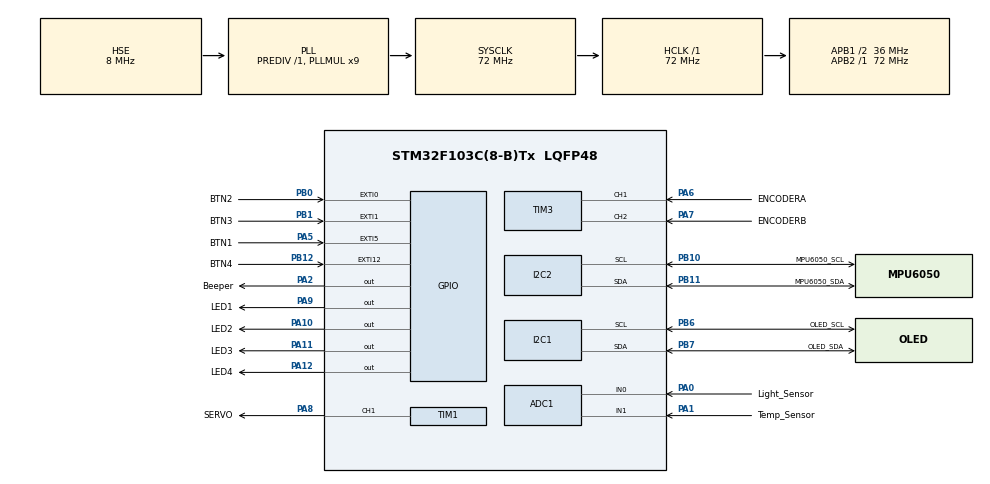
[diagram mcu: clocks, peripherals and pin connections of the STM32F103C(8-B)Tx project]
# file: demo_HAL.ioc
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ADC1.Channel-2\#ChannelRegularConversion=ADC_CHANNEL_0
ADC1.Channel-3\#ChannelRegularConversion=ADC_CHANNEL_1
ADC1.ContinuousConvMode=ENABLE
ADC1.NbrOfConversion=2
ADC1.NbrOfConversionFlag=1
ADC1.Rank-2\#ChannelRegularConversion=1
ADC1.Rank-3\#ChannelRegularConversion=2
ADC1.SamplingTime-2\#ChannelRegularConversion=ADC_SAMPLETIME_239CYCLES_5
ADC1.SamplingTime-3\#ChannelRegularConversion=ADC_SAMPLETIME_239CYCLES_5
ADC1.master=1
Dma.ADC1.0.Direction=DMA_PERIPH_TO_MEMORY
Dma.ADC1.0.Instance=DMA1_Channel1
Dma.ADC1.0.MemDataAlignment=DMA_MDATAALIGN_WORD
Dma.ADC1.0.MemInc=DMA_MINC_ENABLE
Dma.ADC1.0.Mode=DMA_CIRCULAR
Dma.ADC1.0.PeriphDataAlignment=DMA_PDATAALIGN_WORD
Dma.ADC1.0.PeriphInc=DMA_PINC_DISABLE
Dma.ADC1.0.Priority=DMA_PRIORITY_HIGH
Dma.Request0=ADC1
I2C1.I2C_Mode=I2C_Standard
Mcu.Family=STM32F1
Mcu.Name=STM32F103C(8-B)Tx
Mcu.Package=LQFP48
NVIC.DMA1_Channel1_IRQn=true\:0\:0\:false\:false\:true\:false\:true\:true
NVIC.EXTI0_IRQn=true\:2\:0\:true\:false\:true\:true\:true\:true
NVIC.EXTI15_10_IRQn=true\:2\:0\:true\:false\:true\:true\:true\:true
NVIC.EXTI1_IRQn=true\:2\:0\:true\:false\:true\:true\:true\:true
NVIC.EXTI9_5_IRQn=true\:2\:0\:true\:false\:true\:true\:true\:true
NVIC.PriorityGroup=NVIC_PRIORITYGROUP_4
PA0-WKUP.GPIO_Label=Light_Sensor
PA0-WKUP.Signal=SharedAnalog_PA0
PA1.GPIO_Label=Temp_Sensor
PA1.Signal=SharedAnalog_PA1
PA10.GPIO_Label=LED2
PA10.GPIO_Speed=GPIO_SPEED_FREQ_HIGH
PA10.PinState=GPIO_PIN_SET
PA10.Signal=GPIO_Output
PA11.GPIO_Label=LED3
PA11.GPIO_Speed=GPIO_SPEED_FREQ_HIGH
PA11.PinState=GPIO_PIN_SET
PA11.Signal=GPIO_Output
PA12.GPIO_Label=LED4
PA12.GPIO_Speed=GPIO_SPEED_FREQ_HIGH
PA12.PinState=GPIO_PIN_SET
PA12.Signal=GPIO_Output
PA13.Mode=Serial_Wire
PA13.Signal=SYS_JTMS-SWDIO
PA14.Mode=Serial_Wire
PA14.Signal=SYS_JTCK-SWCLK
PA2.GPIO_Label=Beeper
PA2.GPIO_Speed=GPIO_SPEED_FREQ_MEDIUM
PA2.PinState=GPIO_PIN_SET
PA2.Signal=GPIO_Output
PA5.GPIO_Label=BTN1
PA5.GPIO_ModeDefaultEXTI=GPIO_MODE_IT_FALLING
PA5.GPIO_PuPd=GPIO_PULLUP
PA5.Signal=GPXTI5
PA6.GPIO_Label=ENCODERA
PA6.GPIO_ModeDefaultPP=GPIO_MODE_AF_PP
PA6.GPIO_PuPd=GPIO_PULLUP
PA6.GPIO_Speed=GPIO_SPEED_FREQ_HIGH
PA6.Signal=S_TIM3_CH1
PA7.GPIO_Label=ENCODERB
PA7.GPIO_PuPd=GPIO_PULLUP
PA7.GPIO_Speed=GPIO_SPEED_FREQ_HIGH
PA7.Signal=S_TIM3_CH2
PA8.GPIO_Label=SERVO
PA8.GPIO_PuPd=GPIO_PULLUP
PA8.Signal=S_TIM1_CH1
PA9.GPIO_Label=LED1
PA9.GPIO_Speed=GPIO_SPEED_FREQ_HIGH
PA9.PinState=GPIO_PIN_SET
PA9.Signal=GPIO_Output
PB0.GPIO_Label=BTN2
PB0.GPIO_ModeDefaultEXTI=GPIO_MODE_IT_FALLING
PB0.GPIO_PuPd=GPIO_PULLUP
PB0.Signal=GPXTI0
PB1.GPIO_Label=BTN3
PB1.GPIO_ModeDefaultEXTI=GPIO_MODE_IT_FALLING
PB1.GPIO_PuPd=GPIO_PULLUP
PB1.Signal=GPXTI1
PB10.GPIO_Label=MPU6050_SCL
PB10.Mode=I2C
PB10.Signal=I2C2_SCL
PB11.GPIO_Label=MPU6050_SDA
PB11.Mode=I2C
PB11.Signal=I2C2_SDA
PB12.GPIO_Label=BTN4
PB12.GPIO_ModeDefaultEXTI=GPIO_MODE_IT_FALLING
PB12.GPIO_PuPd=GPIO_PULLUP
PB12.Signal=GPXTI12
PB6.GPIO_Label=OLED_SCL
PB6.Mode=I2C
PB6.Signal=I2C1_SCL
PB7.GPIO_Label=OLED_SDA
PB7.Mode=I2C
PB7.Signal=I2C1_SDA
PC14-OSC32_IN.Mode=LSE-External-Oscillator
PC14-OSC32_IN.Signal=RCC_OSC32_IN
PC15-OSC32_OUT.Mode=LSE-External-Oscillator
PC15-OSC32_OUT.Signal=RCC_OSC32_OUT
PD0-OSC_IN.Mode=HSE-External-Oscillator
PD0-OSC_IN.Signal=RCC_OSC_IN
PD1-OSC_OUT.Mode=HSE-External-Oscillator
PD1-OSC_OUT.Signal=RCC_OSC_OUT
ProjectManager.HeapSize=0x200
ProjectManager.StackSize=0x400
ProjectManager.TargetToolchain=MDK-ARM V5.32
RCC.ADCPresc=RCC_ADCPCLK2_DIV6
RCC.AHBFreq_Value=72000000
RCC.APB1CLKDivider=RCC_HCLK_DIV2
RCC.APB1Freq_Value=36000000
RCC.APB1TimFreq_Value=72000000
RCC.APB2Freq_Value=72000000
RCC.APB2TimFreq_Value=72000000
RCC.HCLKFreq_Value=72000000
RCC.PLLMUL=RCC_PLL_MUL9
RCC.PLLSourceVirtual=RCC_PLLSOURCE_HSE
RCC.SYSCLKFreq_VALUE=72000000
RCC.SYSCLKSource=RCC_SYSCLKSOURCE_PLLCLK
RCC.USBFreq_Value=72000000
SH.S_TIM1_CH1.0=TIM1_CH1,PWM Generation1 CH1
SH.S_TIM3_CH1.0=TIM3_CH1,Encoder_Interface
SH.S_TIM3_CH2.0=TIM3_CH2,Encoder_Interface
SH.SharedAnalog_PA0.0=GPIO_Analog
SH.SharedAnalog_PA0.1=ADC1_IN0,IN0
SH.SharedAnalog_PA1.0=GPIO_Analog
SH.SharedAnalog_PA1.1=ADC1_IN1,IN1
TIM1.Channel-PWM\ Generation1\ CH1=TIM_CHANNEL_1
TIM1.Period=20000-1
TIM1.Prescaler=72-1
TIM1.Pulse-PWM\ Generation1\ CH1=1500
TIM3.IC1Filter=15
TIM3.IC2Filter=15
VP_TIM1_VS_ClockSourceINT.Mode=Internal
board=custom

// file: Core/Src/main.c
/* USER CODE BEGIN Header */
/**
 ******************************************************************************
 * @file           : main.c
 * @brief          : Main program body
 ******************************************************************************
 * @attention
 *
 * Copyright (c) 2025 STMicroelectronics.
 * All rights reserved.
 *
 * This software is licensed under terms that can be found in the LICENSE file
 * in the root directory of this software component.
 * If no LICENSE file comes with this software, it is provided AS-IS.
 *
 ******************************************************************************
 */
/* USER CODE END Header */
#include "main.h"
#include "adc.h"
#include "dma.h"
#include "i2c.h"
#include "tim.h"
#include "gpio.h"

/* USER CODE BEGIN Includes */
#include "system.h"
/* USER CODE END Includes */

void SystemClock_Config(void);

int main(void)
{

  /* MCU Configuration--------------------------------------------------------*/

  /* Reset of all peripherals, Initializes the Flash interface and the Systick. */
  HAL_Init();

  /* Configure the system clock */
  SystemClock_Config();

  /* Initialize all configured peripherals */
  MX_GPIO_Init();
  MX_DMA_Init();
  MX_I2C1_Init();
  MX_TIM3_Init();
  MX_ADC1_Init();
  MX_I2C2_Init();
  MX_TIM1_Init();
  /* USER CODE BEGIN 2 */
  System_Init();
  /* USER CODE END 2 */

  /* Infinite loop */
  while (1)
  {

    /* USER CODE BEGIN 3 */
    // ϵͳ������
    System_Process();

    HAL_Delay(10); // delay 10ms
  }
  /* USER CODE END 3 */
}

void SystemClock_Config(void)
{
  RCC_OscInitTypeDef RCC_OscInitStruct = {0};
  RCC_ClkInitTypeDef RCC_ClkInitStruct = {0};
  RCC_PeriphCLKInitTypeDef PeriphClkInit = {0};

  /** Initializes the RCC Oscillators according to the specified parameters
   * in the RCC_OscInitTypeDef structure.
   */
  RCC_OscInitStruct.OscillatorType = RCC_OSCILLATORTYPE_HSE;
  RCC_OscInitStruct.HSEState = RCC_HSE_ON;
  RCC_OscInitStruct.HSEPredivValue = RCC_HSE_PREDIV_DIV1;
  RCC_OscInitStruct.HSIState = RCC_HSI_ON;
  RCC_OscInitStruct.PLL.PLLState = RCC_PLL_ON;
  RCC_OscInitStruct.PLL.PLLSource = RCC_PLLSOURCE_HSE;
  RCC_OscInitStruct.PLL.PLLMUL = RCC_PLL_MUL9;
  if (HAL_RCC_OscConfig(&RCC_OscInitStruct) != HAL_OK)
  {
    Error_Handler();
  }

  /** Initializes the CPU, AHB and APB buses clocks
   */
  RCC_ClkInitStruct.ClockType = RCC_CLOCKTYPE_HCLK | RCC_CLOCKTYPE_SYSCLK | RCC_CLOCKTYPE_PCLK1 | RCC_CLOCKTYPE_PCLK2;
  RCC_ClkInitStruct.SYSCLKSource = RCC_SYSCLKSOURCE_PLLCLK;
  RCC_ClkInitStruct.AHBCLKDivider = RCC_SYSCLK_DIV1;
  RCC_ClkInitStruct.APB1CLKDivider = RCC_HCLK_DIV2;
  RCC_ClkInitStruct.APB2CLKDivider = RCC_HCLK_DIV1;

  if (HAL_RCC_ClockConfig(&RCC_ClkInitStruct, FLASH_LATENCY_2) != HAL_OK)
  {
    Error_Handler();
  }
  PeriphClkInit.PeriphClockSelection = RCC_PERIPHCLK_ADC;
  PeriphClkInit.AdcClockSelection = RCC_ADCPCLK2_DIV6;
  if (HAL_RCCEx_PeriphCLKConfig(&PeriphClkInit) != HAL_OK)
  {
    Error_Handler();
  }
}

void Error_Handler(void)
{
  __disable_irq();
  while (1)
  {
  }
}
